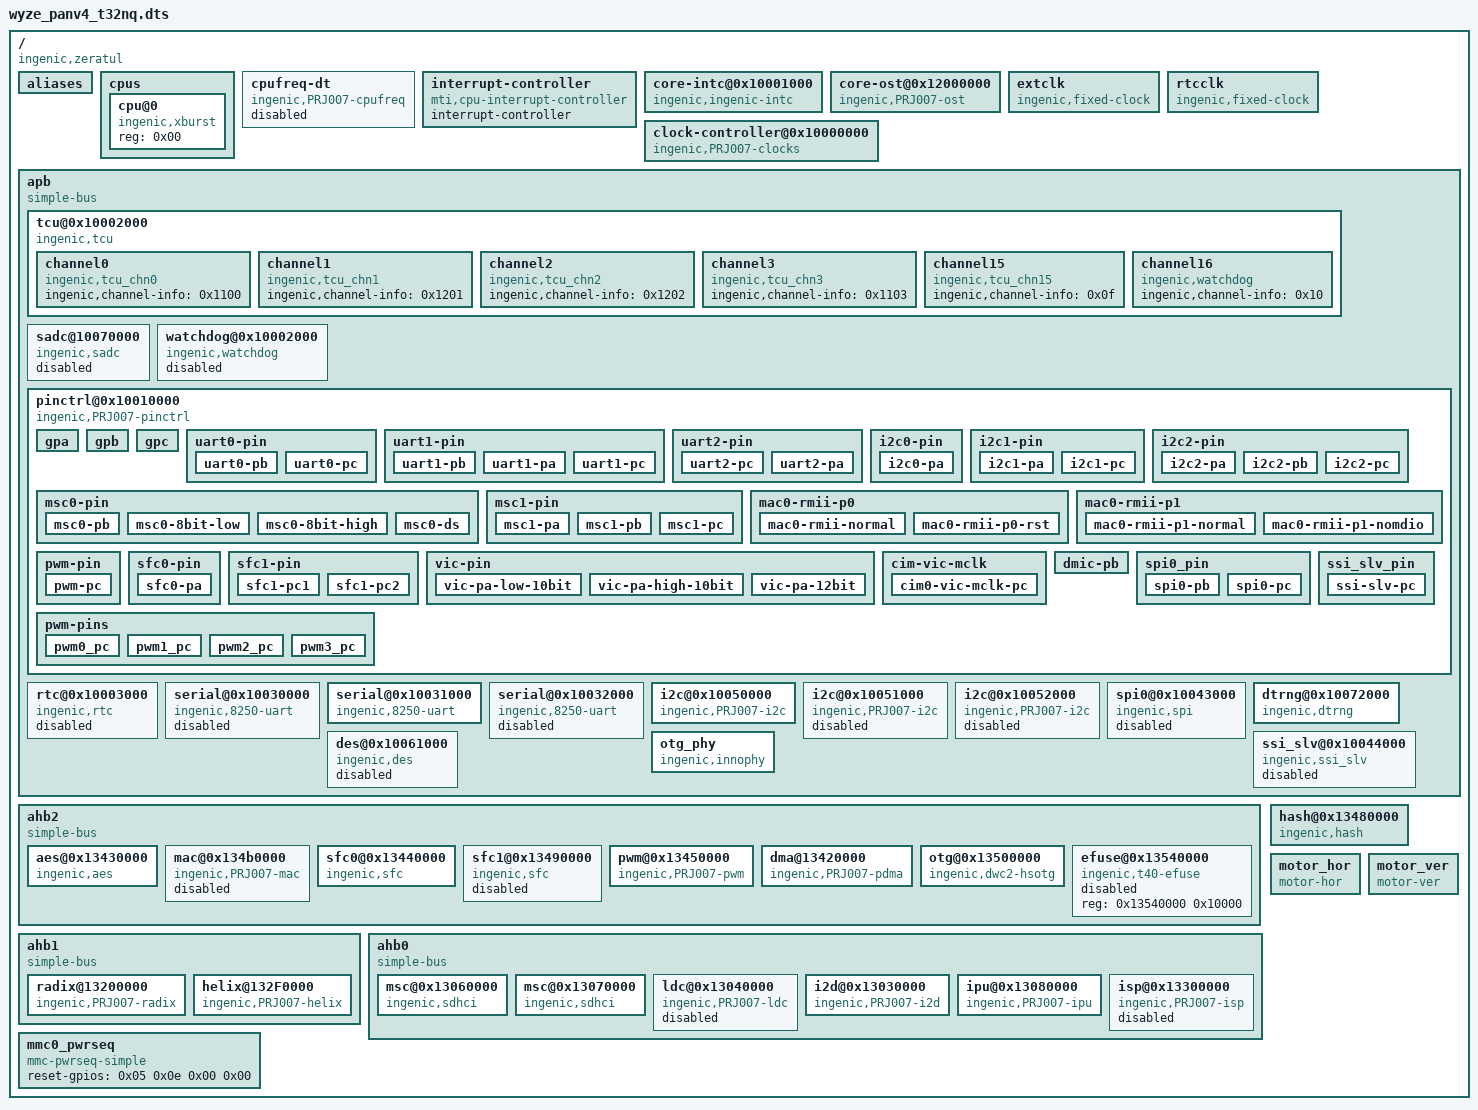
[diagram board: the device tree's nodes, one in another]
/dts-v1/;

/ {
	#address-cells = <0x01>;
	#size-cells = <0x01>;
	compatible = "ingenic,zeratul", "ingenic,PRJ007";

	aliases {
		i2c0 = "/apb/i2c@0x10050000";
		i2c1 = "/apb/i2c@0x10051000";
		i2c2 = "/apb/i2c@0x10052000";
		uart0 = "/apb/serial@0x10030000";
		uart1 = "/apb/serial@0x10031000";
		uart2 = "/apb/serial@0x10032000";
		msc0 = "/ahb0/msc@0x13060000";
		msc1 = "/ahb0/msc@0x13070000";
		mac0 = "/ahb2/mac@0x134b0000";
		spi0 = "/apb/spi0@0x10043000";
		sfc0 = "/ahb2/sfc0@0x13440000";
		sfc1 = "/ahb2/sfc1@0x13490000";
	};

	cpus {
		#address-cells = <0x01>;
		#size-cells = <0x00>;

		cpu@0 {
			compatible = "ingenic,xburst";
			reg = <0x00>;
		};
	};

	cpufreq-dt {
		compatible = "ingenic,PRJ007-cpufreq";
		status = "disabled";
	};

	interrupt-controller {
		#address-cells = <0x00>;
		#interrupt-cells = <0x01>;
		interrupt-controller;
		compatible = "mti,cpu-interrupt-controller";
		linux,phandle = <0x01>;
		phandle = <0x01>;
	};

	core-intc@0x10001000 {
		compatible = "ingenic,ingenic-intc";
		reg = <0x10001000 0x50>;
		interrupt-controller;
		#interrupt-cells = <0x01>;
		interrupt-parent = <0x01>;
		interrupts = <0x02>;
		interrupt-names = "intc";
		linux,phandle = <0x04>;
		phandle = <0x04>;
	};

	core-ost@0x12000000 {
		compatible = "ingenic,PRJ007-ost";
		reg = <0x12000000 0x30>;
		interrupt-parent = <0x01>;
		interrupt-names = "sys_ost";
		interrupts = <0x04>;
	};

	extclk {
		compatible = "ingenic,fixed-clock";
		clock-output-names = "ext";
		#clock-cells = <0x00>;
		clock-frequency = <0x16e3600>;
		linux,phandle = <0x02>;
		phandle = <0x02>;
	};

	rtcclk {
		compatible = "ingenic,fixed-clock";
		clock-output-names = "rtc_ext";
		#clock-cells = <0x00>;
		clock-frequency = <0x8000>;
		linux,phandle = <0x03>;
		phandle = <0x03>;
	};

	clock-controller@0x10000000 {
		compatible = "ingenic,PRJ007-clocks";
		reg = <0x10000000 0x100>;
		clocks = <0x02 0x03>;
		clock-names = "ext", "rtc_ext";
		#clock-cells = <0x01>;
		little-endian;
	};

	apb {
		compatible = "simple-bus";
		#address-cells = <0x01>;
		#size-cells = <0x01>;
		ranges;

		tcu@0x10002000 {
			compatible = "ingenic,tcu";
			reg = <0x10002000 0x140>;
			interrupt-parent = <0x04>;
			interrupt-names = "tcu_int0", "tcu_int1", "tcu_int2";
			interrupts = <0x1b 0x1a 0x19>;
			interrupt-controller;
			status = "ok";

			channel0 {
				compatible = "ingenic,tcu_chn0";
				ingenic,channel-info = <0x1100>;
			};

			channel1 {
				compatible = "ingenic,tcu_chn1";
				ingenic,channel-info = <0x1201>;
			};

			channel2 {
				compatible = "ingenic,tcu_chn2";
				ingenic,channel-info = <0x1202>;
			};

			channel3 {
				compatible = "ingenic,tcu_chn3";
				ingenic,channel-info = <0x1103>;
			};

			channel15 {
				compatible = "ingenic,tcu_chn15";
				ingenic,channel-info = <0x0f>;
			};

			channel16 {
				compatible = "ingenic,watchdog";
				ingenic,channel-info = <0x10>;
			};
		};

		sadc@10070000 {
			compatible = "ingenic,sadc";
			reg = <0x10070000 0x1000>;
			interrupt-parent = <0x04>;
			interrupts = <0x12>;
			status = "disabled";
		};

		watchdog@0x10002000 {
			compatible = "ingenic,watchdog";
			reg = <0x10002000 0x1000>;
			interrupt-parent = <0x04>;
			interrupts = <0x1b>;
			status = "disabled";
		};

		pinctrl@0x10010000 {
			compatible = "ingenic,PRJ007-pinctrl";
			reg = <0x10010000 0x1000>;
			ingenic,num-chips = <0x03>;
			ingenic,regs-offset = <0x100>;

			gpa {
				gpio-controller;
				#gpio-cells = <0x03>;
				#ingenic,pincfg-cells = <0x03>;
				#ingenic,pinmux-cells = <0x02>;
				interrupts = <0x11>;
				interrupt-parent = <0x04>;
				interrupt-controller;
				#interrupt-cells = <0x03>;
				ingenic,num-gpios = <0x20>;
				ingenic,pull-gpios-low = <0x55555555>;
				ingenic,pull-gpios-high = <0x55555555>;
				linux,phandle = <0x07>;
				phandle = <0x07>;
			};

			gpb {
				gpio-controller;
				#gpio-cells = <0x03>;
				#ingenic,pincfg-cells = <0x03>;
				#ingenic,pinmux-cells = <0x02>;
				interrupts = <0x10>;
				interrupt-parent = <0x04>;
				interrupt-controller;
				#interrupt-cells = <0x03>;
				ingenic,num-gpios = <0x20>;
				ingenic,pull-gpios-low = <0x55555555>;
				ingenic,pull-gpios-high = <0x55555555>;
				linux,phandle = <0x05>;
				phandle = <0x05>;
			};

			gpc {
				gpio-controller;
				#gpio-cells = <0x03>;
				#ingenic,pincfg-cells = <0x03>;
				#ingenic,pinmux-cells = <0x02>;
				interrupts = <0x0f>;
				interrupt-parent = <0x04>;
				interrupt-controller;
				#interrupt-cells = <0x03>;
				ingenic,num-gpios = <0x20>;
				ingenic,pull-gpios-low = <0x55555555>;
				ingenic,pull-gpios-high = <0x55555555>;
				linux,phandle = <0x06>;
				phandle = <0x06>;
			};

			uart0-pin {

				uart0-pb {
					ingenic,pinmux = <0x05 0x13 0x16>;
					ingenic,pinmux-funcsel = <0x00>;
					linux,phandle = <0x08>;
					phandle = <0x08>;
				};

				uart0-pc {
					ingenic,pinmux = <0x06 0x08 0x09>;
					ingenic,pinmux-funcsel = <0x00>;
				};
			};

			uart1-pin {

				uart1-pb {
					ingenic,pinmux = <0x05 0x17 0x18>;
					ingenic,pinmux-funcsel = <0x00>;
					linux,phandle = <0x09>;
					phandle = <0x09>;
				};

				uart1-pa {
					ingenic,pinmux = <0x07 0x06 0x07>;
					ingenic,pinmux-funcsel = <0x02>;
				};

				uart1-pc {
					ingenic,pinmux = <0x06 0x08 0x09>;
					ingenic,pinmux-funcsel = <0x00>;
				};
			};

			uart2-pin {

				uart2-pc {
					ingenic,pinmux = <0x06 0x1a 0x1d>;
					ingenic,pinmux-funcsel = <0x03>;
					linux,phandle = <0x0a>;
					phandle = <0x0a>;
				};

				uart2-pa {
					ingenic,pinmux = <0x07 0x15 0x16>;
					ingenic,pinmux-funcsel = <0x03>;
				};
			};

			i2c0-pin {

				i2c0-pa {
					ingenic,pinmux = <0x07 0x0c 0x0d>;
					ingenic,pinmux-funcsel = <0x00>;
					linux,phandle = <0x0b>;
					phandle = <0x0b>;
				};
			};

			i2c1-pin {

				i2c1-pa {
					ingenic,pinmux = <0x07 0x0e 0x0f>;
					ingenic,pinmux-funcsel = <0x00>;
				};

				i2c1-pc {
					ingenic,pinmux = <0x06 0x06 0x07>;
					ingenic,pinmux-funcsel = <0x03>;
				};
			};

			i2c2-pin {

				i2c2-pa {
					ingenic,pinmux = <0x07 0x12 0x13>;
					ingenic,pinmux-funcsel = <0x02>;
				};

				i2c2-pb {
					ingenic,pinmux = <0x05 0x19 0x1a>;
					ingenic,pinmux-funcsel = <0x00>;
				};

				i2c2-pc {
					ingenic,pinmux = <0x06 0x08 0x09>;
					ingenic,pinmux-funcsel = <0x01>;
				};
			};

			msc0-pin {

				msc0-pb {
					ingenic,pinmux = <0x05 0x00 0x05>;
					ingenic,pinmux-funcsel = <0x00>;
					linux,phandle = <0x10>;
					phandle = <0x10>;
				};

				msc0-8bit-low {
					ingenic,pinmux = <0x05 0x00 0x05>;
					ingenic,pinmux-funcsel = <0x00>;
				};

				msc0-8bit-high {
					ingenic,pinmux = <0x07 0x13 0x16>;
					ingenic,pinmux-funcsel = <0x00>;
				};

				msc0-ds {
					ingenic,pinmux = <0x07 0x12 0x12>;
					ingenic,pinmux-funcsel = <0x00>;
				};
			};

			msc1-pin {

				msc1-pa {
					ingenic,pinmux = <0x07 0x0e 0x0f 0x07 0x11 0x11 0x07 0x14 0x16>;
					ingenic,pinmux-funcsel = <0x02>;
				};

				msc1-pb {
					ingenic,pinmux = <0x05 0x08 0x0b 0x05 0x0d 0x0e>;
					ingenic,pinmux-funcsel = <0x01>;
				};

				msc1-pc {
					ingenic,pinmux = <0x06 0x02 0x07>;
					ingenic,pinmux-funcsel = <0x00>;
					linux,phandle = <0x12>;
					phandle = <0x12>;
				};
			};

			mac0-rmii-p0 {

				mac0-rmii-normal {
					ingenic,pinmux = <0x05 0x0f 0x10 0x05 0x09 0x09>;
					ingenic,pinmux-funcsel = <0x00>;
				};

				mac0-rmii-p0-rst {
					ingenic,pinmux = <0x05 0x0f 0x10 0x05 0x09 0x09>;
					ingenic,pinmux-funcsel = <0x04>;
				};
			};

			mac0-rmii-p1 {

				mac0-rmii-p1-normal {
					ingenic,pinmux = <0x05 0x07 0x07 0x05 0x0d 0x0e 0x05 0x08 0x08 0x05 0x0a 0x0b 0x05 0x06 0x06>;
					ingenic,pinmux-funcsel = <0x00>;
				};

				mac0-rmii-p1-nomdio {
					ingenic,pinmux = <0x05 0x07 0x07 0x05 0x0d 0x0e 0x05 0x08 0x08 0x05 0x06 0x06>;
					ingenic,pinmux-funcsel = <0x00>;
				};
			};

			pwm-pin {

				pwm-pc {
					ingenic,pinmux = <0x06 0x02 0x07>;
					ingenic,pinmux-funcsel = <0x02>;
				};
			};

			sfc0-pin {

				sfc0-pa {
					ingenic,pinmux = <0x07 0x17 0x1c>;
					ingenic,pinmux-funcsel = <0x00>;
					linux,phandle = <0x0d>;
					phandle = <0x0d>;
				};
			};

			sfc1-pin {

				sfc1-pc1 {
					ingenic,pinmux = <0x06 0x02 0x07>;
					ingenic,pinmux-funcsel = <0x01>;
					linux,phandle = <0x0e>;
					phandle = <0x0e>;
				};

				sfc1-pc2 {
					ingenic,pinmux = <0x06 0x0b 0x10>;
					ingenic,pinmux-funcsel = <0x00>;
				};
			};

			vic-pin {

				vic-pa-low-10bit {
					ingenic,pinmux = <0x07 0x00 0x09 0x07 0x0c 0x0e>;
					ingenic,pinmux-funcsel = <0x00>;
				};

				vic-pa-high-10bit {
					ingenic,pinmux = <0x07 0x02 0x0e>;
					ingenic,pinmux-funcsel = <0x00>;
				};

				vic-pa-12bit {
					ingenic,pinmux = <0x07 0x00 0x0e>;
					ingenic,pinmux-funcsel = <0x00>;
				};
			};

			cim-vic-mclk {

				cim0-vic-mclk-pc {
					ingenic,pinmux = <0x06 0x1f 0x1f>;
					ingenic,pinmux-funcsel = <0x01>;
				};
			};

			dmic-pb {
				ingenic,pinmux = <0x05 0x1c 0x1e>;
				ingenic,pinmux-funcsel = <0x03>;
			};

			spi0_pin {

				spi0-pb {
					ingenic,pinmux = <0x05 0x19 0x1c>;
					ingenic,pinmux-funcsel = <0x02>;
				};

				spi0-pc {
					ingenic,pinmux = <0x06 0x0b 0x10>;
					ingenic,pinmux-funcsel = <0x01>;
				};
			};

			ssi_slv_pin {

				ssi-slv-pc {
					ingenic,pinmux = <0x06 0x11 0x16>;
					ingenic,pinmux-funcsel = <0x00>;
				};
			};

			pwm-pins {

				pwm0_pc {
					ingenic,pinmux = <0x06 0x11 0x11>;
					ingenic,pinmux-funcsel = <0x00>;
				};

				pwm1_pc {
					ingenic,pinmux = <0x06 0x12 0x12>;
					ingenic,pinmux-funcsel = <0x00>;
				};

				pwm2_pc {
					ingenic,pinmux = <0x06 0x13 0x13>;
					ingenic,pinmux-funcsel = <0x00>;
				};

				pwm3_pc {
					ingenic,pinmux = <0x06 0x14 0x14>;
					ingenic,pinmux-funcsel = <0x00>;
				};
			};
		};

		rtc@0x10003000 {
			compatible = "ingenic,rtc";
			reg = <0x10003000 0x1000>;
			interrupt-parent = <0x04>;
			interrupts = <0x20>;
			status = "disabled";
		};

		serial@0x10030000 {
			compatible = "ingenic,8250-uart";
			reg = <0x10030000 0x1000>;
			reg-shift = <0x02>;
			interrupt-parent = <0x04>;
			interrupts = <0x33>;
			pinctrl-names = "default";
			pinctrl-0 = <0x08>;
			status = "disabled";
		};

		serial@0x10031000 {
			compatible = "ingenic,8250-uart";
			reg = <0x10031000 0x1000>;
			reg-shift = <0x02>;
			interrupt-parent = <0x04>;
			interrupts = <0x32>;
			pinctrl-names = "default";
			pinctrl-0 = <0x09>;
			status = "okay";
		};

		serial@0x10032000 {
			compatible = "ingenic,8250-uart";
			reg = <0x10032000 0x1000>;
			reg-shift = <0x02>;
			interrupt-parent = <0x04>;
			interrupts = <0x31>;
			pinctrl-names = "default";
			pinctrl-0 = <0x0a>;
			status = "disabled";
		};

		i2c@0x10050000 {
			compatible = "ingenic,PRJ007-i2c";
			reg = <0x10050000 0x1000>;
			interrupt-parent = <0x04>;
			interrupts = <0x3c>;
			#address-cells = <0x01>;
			#size-cells = <0x00>;
			status = "okay";
			pinctrl-0 = <0x0b>;
			pinctrl-names = "default";
			clock-frequency = <0x61a80>;
		};

		i2c@0x10051000 {
			compatible = "ingenic,PRJ007-i2c";
			reg = <0x10051000 0x1000>;
			interrupt-parent = <0x04>;
			interrupts = <0x3b>;
			#address-cells = <0x01>;
			#size-cells = <0x00>;
			status = "disabled";
		};

		i2c@0x10052000 {
			compatible = "ingenic,PRJ007-i2c";
			reg = <0x10052000 0x1000>;
			interrupt-parent = <0x04>;
			interrupts = <0x30>;
			#address-cells = <0x01>;
			#size-cells = <0x00>;
			status = "disabled";
		};

		spi0@0x10043000 {
			compatible = "ingenic,spi";
			reg = <0x10043000 0x1000>;
			interrupt-parent = <0x04>;
			interrupts = <0x09>;
			dmas = <0x0c 0x16 0x0c 0x17>;
			dma-names = "tx", "rx";
			#address-cells = <0x01>;
			#size-cells = <0x00>;
			status = "disabled";
		};

		dtrng@0x10072000 {
			compatible = "ingenic,dtrng";
			reg = <0x10072000 0x100>;
			interrupt-parent = <0x04>;
			interrupts = <0x22>;
			status = "okay";
		};

		ssi_slv@0x10044000 {
			compatible = "ingenic,ssi_slv";
			reg = <0x10044000 0x1000>;
			interrupt-parent = <0x04>;
			interrupts = <0x0e>;
			dmas = <0x0c 0x18 0x0c 0x19>;
			dma-names = "tx", "rx";
			#address-cells = <0x01>;
			#size-cells = <0x00>;
			status = "disabled";
		};

		des@0x10061000 {
			compatible = "ingenic,des";
			reg = <0x10043000 0x1000>;
			dmas = <0x0c 0x2e 0x0c 0x2f>;
			dma-names = "tx", "rx";
			#address-cells = <0x01>;
			#size-cells = <0x00>;
			status = "disabled";
		};

		otg_phy {
			compatible = "ingenic,innophy", "syscon";
			reg = <0x10000000 0x1000 0x10060000 0x1000>;
			dr_mode = "host";
			status = "okay";
			linux,phandle = <0x0f>;
			phandle = <0x0f>;
		};
	};

	ahb2 {
		compatible = "simple-bus";
		#address-cells = <0x01>;
		#size-cells = <0x01>;
		ranges;

		aes@0x13430000 {
			compatible = "ingenic,aes";
			reg = <0x13430000 0x10000>;
			interrupt-parent = <0x04>;
			interrupts = <0x17>;
			status = "okay";
		};

		mac@0x134b0000 {
			compatible = "ingenic,PRJ007-mac";
			reg = <0x134b0000 0x2000>;
			interrupt-parent = <0x04>;
			interrupts = <0x37>;
			status = "disabled";
			ingenic,rst-ms = <0x0a>;
		};

		sfc0@0x13440000 {
			compatible = "ingenic,sfc";
			reg = <0x13440000 0x10000>;
			interrupt-parent = <0x04>;
			interrupts = <0x07>;
			pinctrl-names = "default";
			pinctrl-0 = <0x0d>;
			status = "okay";
			ingenic,sfc-max-frequency = <0x17d7840>;
			ingenic,use_board_info = [00];
			ingenic,spiflash_param_offset = <0x00>;
			ingenic,spiflash_type = <0x00>;
			driver-strength = <0x08>;
		};

		sfc1@0x13490000 {
			compatible = "ingenic,sfc";
			reg = <0x13490000 0x10000>;
			interrupt-parent = <0x04>;
			interrupts = <0x0d>;
			pinctrl-names = "default";
			pinctrl-0 = <0x0e>;
			status = "disabled";
		};

		pwm@0x13450000 {
			compatible = "ingenic,PRJ007-pwm";
			reg = <0x13450000 0x1000>;
			interrupt-parent = <0x04>;
			interrupts = <0x38>;
			#address-cells = <0x01>;
			#size-cells = <0x00>;
			status = "okay";
		};

		dma@13420000 {
			compatible = "ingenic,PRJ007-pdma";
			reg = <0x13420000 0x10000>;
			interrupt-parent = <0x04>;
			interrupt-names = "pdma", "pdmam";
			interrupts = <0x0a 0x3d>;
			#dma-channels = <0x20>;
			#dma-cells = <0x01>;
			ingenic,reserved-chs = <0x03>;
			status = "okay";
			linux,phandle = <0x0c>;
			phandle = <0x0c>;
		};

		otg@0x13500000 {
			compatible = "ingenic,dwc2-hsotg";
			reg = <0x13500000 0x40000>;
			interrupt-parent = <0x04>;
			interrupts = <0x15>;
			ingenic,usbphy = <0x0f>;
			status = "okay";
			g-use-dma;
			dr_mode = "host";
		};

		efuse@0x13540000 {
			compatible = "ingenic,t40-efuse";
			reg = <0x13540000 0x10000>;
			status = "disabled";
		};
	};

	ahb1 {
		compatible = "simple-bus";
		#address-cells = <0x01>;
		#size-cells = <0x01>;
		ranges;

		radix@13200000 {
			compatible = "ingenic,PRJ007-radix";
			reg = <0x13200000 0xf0000>;
			interrupt-parent = <0x04>;
			interrupts = <0x3e>;
			status = "okay";
		};

		helix@132F0000 {
			compatible = "ingenic,PRJ007-helix";
			reg = <0x132f0000 0x10000>;
			interrupt-parent = <0x04>;
			interrupts = <0x3f>;
			status = "okay";
		};
	};

	ahb0 {
		compatible = "simple-bus";
		#address-cells = <0x01>;
		#size-cells = <0x01>;
		ranges;

		msc@0x13060000 {
			compatible = "ingenic,sdhci";
			reg = <0x13060000 0x10000>;
			status = "okay";
			interrupt-parent = <0x04>;
			interrupts = <0x25>;
			pinctrl-names = "default";
			pinctrl-0 = <0x10>;
			cap-mmc-highspeed;
			max-frequency = <0x17d7840>;
			bus-width = <0x04>;
			voltage-ranges = <0x708 0xce4>;
			cd-inverted;
			ingenic,cd-gpios = <0x05 0x0a 0x01 0x00>;
			ingenic,wp-gpios = <0x00>;
			ingenic,rst-gpios = <0x00>;
			driver-strength = <0x08>;
			gpio-pull-flag = <0x01>;
			mmc-pwrseq = <0x11>;
		};

		msc@0x13070000 {
			compatible = "ingenic,sdhci";
			reg = <0x13070000 0x10000>;
			status = "okay";
			interrupt-parent = <0x04>;
			interrupts = <0x24>;
			pinctrl-names = "default";
			pinctrl-0 = <0x12>;
			cap-mmc-highspeed;
			max-frequency = <0x17d7840>;
			bus-width = <0x04>;
			voltage-ranges = <0x708 0xce4>;
			ingenic,sdio_clk = <0x01>;
			ingenic,wp-gpios = <0x00>;
			ingenic,rst-gpios = <0x00>;
			driver-strength = <0x08>;
			gpio-pull-flag = <0x01>;
		};

		ldc@0x13040000 {
			compatible = "ingenic,PRJ007-ldc";
			reg = <0x13040000 0x10000>;
			interrupt-parent = <0x04>;
			interrupts = <0x26>;
			status = "disabled";
		};

		i2d@0x13030000 {
			compatible = "ingenic,PRJ007-i2d";
			reg = <0x13030000 0x10000>;
			interrupt-parent = <0x04>;
			interrupts = <0x27>;
			status = "okay";
		};

		ipu@0x13080000 {
			compatible = "ingenic,PRJ007-ipu";
			reg = <0x13080000 0x10000>;
			interrupt-parent = <0x04>;
			interrupts = <0x06>;
			status = "okay";
		};

		isp@0x13300000 {
			compatible = "ingenic,PRJ007-isp";
			reg = <0x13300000 0x100000>;
			interrupt-parent = <0x04>;
			interrupts = <0x1d>;
			status = "disabled";
		};
	};

	hash@0x13480000 {
		compatible = "ingenic,hash";
		reg = <0x13480000 0x10000>;
		interrupt-parent = <0x04>;
		interrupts = <0x16>;
		status = "okay";
	};

	mmc0_pwrseq {
		compatible = "mmc-pwrseq-simple";
		reset-gpios = <0x05 0x0e 0x00 0x00>;
		linux,phandle = <0x11>;
		phandle = <0x11>;
	};

	motor_hor {
		status = "okay";
		compatible = "motor-hor";
		motor1-gpios = <0x05 0x1e 0x00 0x00>;
		motor2-gpios = <0x05 0x1c 0x00 0x00>;
		motor3-gpios = <0x05 0x1b 0x00 0x00>;
		motor4-gpios = <0x05 0x10 0x00 0x00>;
	};

	motor_ver {
		status = "okay";
		compatible = "motor-ver";
		motor1-gpios = <0x05 0x0d 0x00 0x00>;
		motor2-gpios = <0x05 0x09 0x00 0x00>;
		motor3-gpios = <0x05 0x1a 0x00 0x00>;
		motor4-gpios = <0x05 0x19 0x00 0x00>;
	};
};
